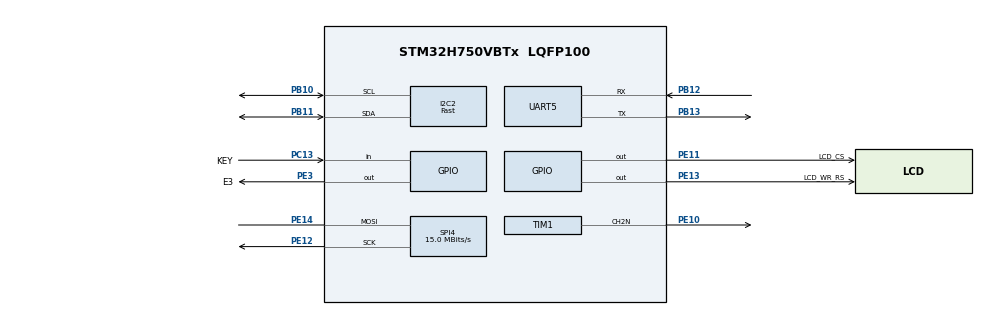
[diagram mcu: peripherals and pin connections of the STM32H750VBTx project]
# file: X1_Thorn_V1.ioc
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ADC3.Channel-2\#ChannelRegularConversion=ADC_CHANNEL_TEMPSENSOR
ADC3.DiscontinuousConvMode=ENABLE
ADC3.NbrOfConversion=1
ADC3.NbrOfConversionFlag=1
ADC3.OffsetNumber-2\#ChannelRegularConversion=ADC_OFFSET_NONE
ADC3.OffsetSignedSaturation-2\#ChannelRegularConversion=DISABLE
ADC3.Rank-2\#ChannelRegularConversion=1
ADC3.SamplingTime-2\#ChannelRegularConversion=ADC_SAMPLETIME_387CYCLES_5
CORTEX_M7.default_mode_Activation=1
I2C2.I2C_Speed_Mode=I2C_Fast
I2C2.Timing=0x00B03FDB
Mcu.Family=STM32H7
Mcu.Name=STM32H750VBTx
Mcu.Package=LQFP100
NVIC.PriorityGroup=NVIC_PRIORITYGROUP_4
NVIC.TIM17_IRQn=true\:0\:0\:false\:false\:true\:true\:true\:true
NVIC.UART5_IRQn=true\:0\:0\:false\:false\:true\:true\:true\:true
PA13\ (JTMS/SWDIO).Mode=Serial_Wire
PA13\ (JTMS/SWDIO).Signal=DEBUG_JTMS-SWDIO
PA14\ (JTCK/SWCLK).Mode=Serial_Wire
PA14\ (JTCK/SWCLK).Signal=DEBUG_JTCK-SWCLK
PB10.GPIO_Pu=GPIO_PULLUP
PB10.Mode=I2C
PB10.Signal=I2C2_SCL
PB11.GPIO_Pu=GPIO_PULLUP
PB11.GPIO_Speed=GPIO_SPEED_FREQ_HIGH
PB11.Mode=I2C
PB11.Signal=I2C2_SDA
PB12.Mode=Asynchronous
PB12.Signal=UART5_RX
PB13.Mode=Asynchronous
PB13.Signal=UART5_TX
PC13.GPIO_Label=KEY
PC13.GPIO_PuPd=GPIO_PULLDOWN
PC13.Signal=GPIO_Input
PC14-OSC32_IN\ (OSC32_IN).Mode=LSE-External-Oscillator
PC14-OSC32_IN\ (OSC32_IN).Signal=RCC_OSC32_IN
PC15-OSC32_OUT\ (OSC32_OUT).Mode=LSE-External-Oscillator
PC15-OSC32_OUT\ (OSC32_OUT).Signal=RCC_OSC32_OUT
PE10.Mode=PWM Generation2 CH2N
PE10.Signal=TIM1_CH2N
PE11.GPIO_Label=LCD_CS
PE11.GPIO_Speed=GPIO_SPEED_FREQ_VERY_HIGH
PE11.Signal=GPIO_Output
PE12.Mode=Simplex_Bidirectional_Master
PE12.Signal=SPI4_SCK
PE13.GPIO_Label=LCD_WR_RS
PE13.GPIO_Speed=GPIO_SPEED_FREQ_VERY_HIGH
PE13.Signal=GPIO_Output
PE14.Mode=Simplex_Bidirectional_Master
PE14.Signal=SPI4_MOSI
PE3.GPIO_Label=E3
PE3.Signal=GPIO_Output
PH0-OSC_IN\ (PH0).Mode=HSE-External-Oscillator
PH0-OSC_IN\ (PH0).Signal=RCC_OSC_IN
PH1-OSC_OUT\ (PH1).Mode=HSE-External-Oscillator
PH1-OSC_OUT\ (PH1).Signal=RCC_OSC_OUT
ProjectManager.HeapSize=0x200
ProjectManager.StackSize=0x400
ProjectManager.TargetToolchain=STM32CubeIDE
RCC.ADCFreq_Value=83333333.33333333
RCC.APB1Freq_Value=120000000
RCC.APB2Freq_Value=120000000
RCC.APB3Freq_Value=120000000
RCC.APB4Freq_Value=120000000
RCC.CortexFreq_Value=480000000
RCC.D1PPRE=RCC_APB3_DIV2
RCC.D2PPRE1=RCC_APB1_DIV2
RCC.D2PPRE2=RCC_APB2_DIV2
RCC.D3PPRE=RCC_APB4_DIV2
RCC.DIVM1=5
RCC.DIVM2=6
RCC.DIVN1=192
RCC.DIVN2=40
RCC.DIVQ2=1
RCC.DIVR3=6
RCC.HCLKFreq_Value=240000000
RCC.HPRE=RCC_HCLK_DIV2
RCC.HSE_VALUE=25000000
RCC.PLLSourceVirtual=RCC_PLLSOURCE_HSE
RCC.RTCClockSelection=RCC_RTCCLKSOURCE_LSE
RCC.SYSCLKFreq_VALUE=480000000
RCC.SYSCLKSource=RCC_SYSCLKSOURCE_PLLCLK
RCC.USBFreq_Value=480000000
SPI4.BaudRatePrescaler=SPI_BAUDRATEPRESCALER_8
SPI4.CalculateBaudRate=15.0 MBits/s
SPI4.DataSize=SPI_DATASIZE_8BIT
SPI4.Direction=SPI_DIRECTION_1LINE
SPI4.Mode=SPI_MODE_MASTER
SPI4.VirtualType=VM_MASTER
TIM1.Channel-PWM\ Generation2\ CH2N=TIM_CHANNEL_2
TIM1.OCNPolarity_2=TIM_OCNPOLARITY_LOW
TIM1.Period=10000-1
TIM1.Prescaler=12-1
TIM17.Channel=TIM_CHANNEL_1
TIM17.Period=9999
TIM17.Prescaler=239
VP_ADC3_TempSens_Input.Mode=IN-TempSens
VP_MEMORYMAP_VS_MEMORYMAP.Mode=CurAppReg
VP_TIM17_VS_ClockSourceINT.Mode=Enable_Timer
VP_TIM17_VS_no_output1.Mode=Output Compare1 No Output
VP_VREFBUF_V_VREFBUF.Mode=ExternalMode
board=custom

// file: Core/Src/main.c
/* USER CODE BEGIN Header */
/**
  ******************************************************************************
  * @file           : main.c
  * @brief          : Main program body
  ******************************************************************************
  * @attention
  *
  * Copyright (c) 2025 STMicroelectronics.
  * All rights reserved.
  *
  * This software is licensed under terms that can be found in the LICENSE file
  * in the root directory of this software component.
  * If no LICENSE file comes with this software, it is provided AS-IS.
  *
  ******************************************************************************
  */
/* USER CODE END Header */
#include "main.h"
#include "adc.h"
#include "i2c.h"
#include "memorymap.h"
#include "spi.h"
#include "tim.h"
#include "usart.h"
#include "gpio.h"

/* USER CODE BEGIN Includes */

#include "C:/Users/marcv/Desktop/X1-Thorn/1_Code/3_STM32/0_workspace/X1_Thorn_V1/Core/Src/User/Test/Test.h"
#include "User/App/MainApp/MainApp.h"

/* USER CODE END Includes */

void SystemClock_Config(void);
static void MPU_Config(void);

int main(void)
{

  /* MPU Configuration--------------------------------------------------------*/
  MPU_Config();

  /* MCU Configuration--------------------------------------------------------*/

  /* Reset of all peripherals, Initializes the Flash interface and the Systick. */
  HAL_Init();

  /* Configure the system clock */
  SystemClock_Config();

  /* Initialize all configured peripherals */
  MX_GPIO_Init();
  MX_TIM1_Init();
  MX_SPI4_Init();
  MX_ADC3_Init();
  MX_TIM17_Init();
  MX_I2C2_Init();
  MX_UART5_Init();
  /* USER CODE BEGIN 2 */

//  main_app();

  Test_Run();

  /* USER CODE END 2 */

  /* Infinite loop */
  while (1)
  {

  }
}

void SystemClock_Config(void)
{
  RCC_OscInitTypeDef RCC_OscInitStruct = {0};
  RCC_ClkInitTypeDef RCC_ClkInitStruct = {0};

  /** Supply configuration update enable
  */
  HAL_PWREx_ConfigSupply(PWR_LDO_SUPPLY);

  /** Configure the main internal regulator output voltage
  */
  __HAL_PWR_VOLTAGESCALING_CONFIG(PWR_REGULATOR_VOLTAGE_SCALE0);

  while(!__HAL_PWR_GET_FLAG(PWR_FLAG_VOSRDY)) {}

  /** Initializes the RCC Oscillators according to the specified parameters
  * in the RCC_OscInitTypeDef structure.
  */
  RCC_OscInitStruct.OscillatorType = RCC_OSCILLATORTYPE_HSE;
  RCC_OscInitStruct.HSEState = RCC_HSE_ON;
  RCC_OscInitStruct.PLL.PLLState = RCC_PLL_ON;
  RCC_OscInitStruct.PLL.PLLSource = RCC_PLLSOURCE_HSE;
  RCC_OscInitStruct.PLL.PLLM = 5;
  RCC_OscInitStruct.PLL.PLLN = 192;
  RCC_OscInitStruct.PLL.PLLP = 2;
  RCC_OscInitStruct.PLL.PLLQ = 2;
  RCC_OscInitStruct.PLL.PLLR = 2;
  RCC_OscInitStruct.PLL.PLLRGE = RCC_PLL1VCIRANGE_2;
  RCC_OscInitStruct.PLL.PLLVCOSEL = RCC_PLL1VCOWIDE;
  RCC_OscInitStruct.PLL.PLLFRACN = 0;
  if (HAL_RCC_OscConfig(&RCC_OscInitStruct) != HAL_OK)
  {
    Error_Handler();
  }

  /** Initializes the CPU, AHB and APB buses clocks
  */
  RCC_ClkInitStruct.ClockType = RCC_CLOCKTYPE_HCLK|RCC_CLOCKTYPE_SYSCLK
                              |RCC_CLOCKTYPE_PCLK1|RCC_CLOCKTYPE_PCLK2
                              |RCC_CLOCKTYPE_D3PCLK1|RCC_CLOCKTYPE_D1PCLK1;
  RCC_ClkInitStruct.SYSCLKSource = RCC_SYSCLKSOURCE_PLLCLK;
  RCC_ClkInitStruct.SYSCLKDivider = RCC_SYSCLK_DIV1;
  RCC_ClkInitStruct.AHBCLKDivider = RCC_HCLK_DIV2;
  RCC_ClkInitStruct.APB3CLKDivider = RCC_APB3_DIV2;
  RCC_ClkInitStruct.APB1CLKDivider = RCC_APB1_DIV2;
  RCC_ClkInitStruct.APB2CLKDivider = RCC_APB2_DIV2;
  RCC_ClkInitStruct.APB4CLKDivider = RCC_APB4_DIV2;

  if (HAL_RCC_ClockConfig(&RCC_ClkInitStruct, FLASH_LATENCY_4) != HAL_OK)
  {
    Error_Handler();
  }
}

 /* MPU Configuration */

void MPU_Config(void)
{
  MPU_Region_InitTypeDef MPU_InitStruct = {0};

  /* Disables the MPU */
  HAL_MPU_Disable();

  /** Initializes and configures the Region and the memory to be protected
  */
  MPU_InitStruct.Enable = MPU_REGION_ENABLE;
  MPU_InitStruct.Number = MPU_REGION_NUMBER0;
  MPU_InitStruct.BaseAddress = 0x0;
  MPU_InitStruct.Size = MPU_REGION_SIZE_4GB;
  MPU_InitStruct.SubRegionDisable = 0x87;
  MPU_InitStruct.TypeExtField = MPU_TEX_LEVEL0;
  MPU_InitStruct.AccessPermission = MPU_REGION_NO_ACCESS;
  MPU_InitStruct.DisableExec = MPU_INSTRUCTION_ACCESS_DISABLE;
  MPU_InitStruct.IsShareable = MPU_ACCESS_SHAREABLE;
  MPU_InitStruct.IsCacheable = MPU_ACCESS_NOT_CACHEABLE;
  MPU_InitStruct.IsBufferable = MPU_ACCESS_NOT_BUFFERABLE;

  HAL_MPU_ConfigRegion(&MPU_InitStruct);
  /* Enables the MPU */
  HAL_MPU_Enable(MPU_PRIVILEGED_DEFAULT);

}

void Error_Handler(void)
{
  __disable_irq();
  while (1)
  {
  }
}
